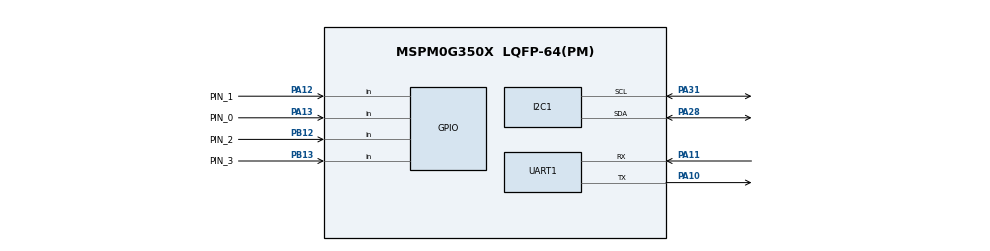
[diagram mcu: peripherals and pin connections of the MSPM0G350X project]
/**
 * @cliArgs --device "MSPM0G350X" --part "Default" --package "LQFP-64(PM)" --product "mspm0_sdk@2.04.00.06"
 * @versions {"tool":"1.23.0+4000"}
 */

/**
 * Import the modules used in this configuration.
 */
const GPIO   = scripting.addModule("/ti/driverlib/GPIO", {}, false);
const GPIO1  = GPIO.addInstance();
const GPIO2  = GPIO.addInstance();
const I2C    = scripting.addModule("/ti/driverlib/I2C", {}, false);
const I2C1   = I2C.addInstance();
const SYSCTL = scripting.addModule("/ti/driverlib/SYSCTL");
const TIMER  = scripting.addModule("/ti/driverlib/TIMER", {}, false);
const TIMER1 = TIMER.addInstance();
const UART   = scripting.addModule("/ti/driverlib/UART", {}, false);
const UART1  = UART.addInstance();

/**
 * Write custom configuration values to the imported modules.
 */
const gate7  = system.clockTree["MFCLKGATE"];
gate7.enable = true;

GPIO1.$name                               = "GPIO_EncoderA";
GPIO1.port                                = "PORTA";
GPIO1.associatedPins.create(2);
GPIO1.associatedPins[0].$name             = "PIN_0";
GPIO1.associatedPins[0].direction         = "INPUT";
GPIO1.associatedPins[0].internalResistor  = "PULL_DOWN";
GPIO1.associatedPins[0].inputFilter       = "8_CYCLES";
GPIO1.associatedPins[0].interruptEn       = true;
GPIO1.associatedPins[0].polarity          = "RISE";
GPIO1.associatedPins[0].interruptPriority = "1";
GPIO1.associatedPins[0].pin.$assign       = "PA13";
GPIO1.associatedPins[1].$name             = "PIN_1";
GPIO1.associatedPins[1].direction         = "INPUT";
GPIO1.associatedPins[1].internalResistor  = "PULL_DOWN";
GPIO1.associatedPins[1].inputFilter       = "8_CYCLES";
GPIO1.associatedPins[1].interruptEn       = true;
GPIO1.associatedPins[1].interruptPriority = "1";
GPIO1.associatedPins[1].polarity          = "RISE";
GPIO1.associatedPins[1].pin.$assign       = "PA12";

const Board = scripting.addModule("/ti/driverlib/Board", {}, false);

GPIO2.$name                               = "GPIO_EncoderB";
GPIO2.port                                = "PORTB";
GPIO2.associatedPins.create(2);
GPIO2.associatedPins[0].$name             = "PIN_2";
GPIO2.associatedPins[0].direction         = "INPUT";
GPIO2.associatedPins[0].internalResistor  = "PULL_DOWN";
GPIO2.associatedPins[0].inputFilter       = "8_CYCLES";
GPIO2.associatedPins[0].interruptEn       = true;
GPIO2.associatedPins[0].interruptPriority = "1";
GPIO2.associatedPins[0].polarity          = "RISE";
GPIO2.associatedPins[0].pin.$assign       = "PB12";
GPIO2.associatedPins[1].$name             = "PIN_3";
GPIO2.associatedPins[1].direction         = "INPUT";
GPIO2.associatedPins[1].interruptEn       = true;
GPIO2.associatedPins[1].interruptPriority = "1";
GPIO2.associatedPins[1].polarity          = "RISE";
GPIO2.associatedPins[1].internalResistor  = "PULL_DOWN";
GPIO2.associatedPins[1].inputFilter       = "8_CYCLES";
GPIO2.associatedPins[1].pin.$assign       = "PB13";

I2C1.$name                             = "I2C";
I2C1.basicEnableController             = true;
I2C1.advAnalogGlitchFilter             = "DISABLED";
I2C1.peripheral.$assign                = "I2C0";
I2C1.peripheral.sdaPin.$assign         = "PA28";
I2C1.peripheral.sclPin.$assign         = "PA31";
I2C1.sdaPinConfig.$name                = "ti_driverlib_gpio_GPIOPinGeneric2";
I2C1.sdaPinConfig.hideOutputInversion  = scripting.forceWrite(false);
I2C1.sdaPinConfig.onlyInternalResistor = scripting.forceWrite(false);
I2C1.sdaPinConfig.passedPeripheralType = scripting.forceWrite("Digital");
I2C1.sclPinConfig.$name                = "ti_driverlib_gpio_GPIOPinGeneric3";
I2C1.sclPinConfig.hideOutputInversion  = scripting.forceWrite(false);
I2C1.sclPinConfig.onlyInternalResistor = scripting.forceWrite(false);
I2C1.sclPinConfig.passedPeripheralType = scripting.forceWrite("Digital");

SYSCTL.forceDefaultClkConfig = true;
SYSCTL.clockTreeEn           = true;

TIMER1.$name              = "TIMER_Encoder_Read";
TIMER1.timerMode          = "PERIODIC";
TIMER1.timerClkPrescale   = 100;
TIMER1.timerPeriod        = "20ms";
TIMER1.interrupts         = ["ZERO"];
TIMER1.interruptPriority  = "1";
TIMER1.peripheral.$assign = "TIMG6";

UART1.$name                    = "UART_0";
UART1.uartClkSrc               = "MFCLK";
UART1.enabledInterrupts        = ["RX"];
UART1.peripheral.$assign       = "UART0";
UART1.peripheral.rxPin.$assign = "PA11";
UART1.peripheral.txPin.$assign = "PA10";
UART1.txPinConfig.$name        = "ti_driverlib_gpio_GPIOPinGeneric0";
UART1.rxPinConfig.$name        = "ti_driverlib_gpio_GPIOPinGeneric1";

/**
 * Pinmux solution for unlocked pins/peripherals. This ensures that minor changes to the automatic solver in a future
 * version of the tool will not impact the pinmux you originally saw.  These lines can be completely deleted in order to
 * re-solve from scratch.
 */
Board.peripheral.$suggestSolution          = "DEBUGSS";
Board.peripheral.swclkPin.$suggestSolution = "PA20";
Board.peripheral.swdioPin.$suggestSolution = "PA19";
